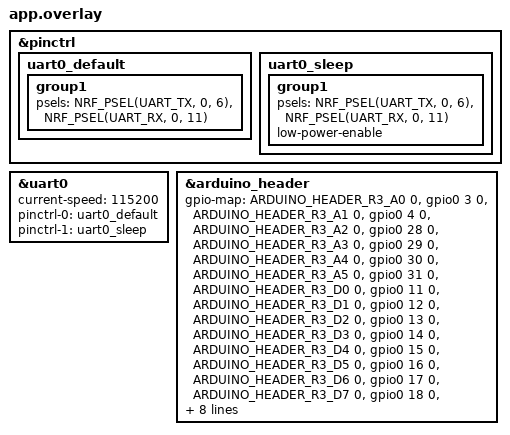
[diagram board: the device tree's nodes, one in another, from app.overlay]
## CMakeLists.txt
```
cmake_minimum_required(VERSION 3.20.0)
find_package(Zephyr REQUIRED HINTS $ENV{ZEPHYR_BASE})
project(gps_trying)

# debugging setup, sets whether we have straight UART outptu or parsed GPS data output
if(CONFIG_GPS_PARSED_OUTPUT)
    target_sources(app PRIVATE src/main_parsed.c)
else()
    target_sources(app PRIVATE src/main_nmea.c)
endif()
```

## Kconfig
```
config GPS_PARSED_OUTPUT
    bool "Use parsed GPS output instead of raw NMEA strings"
    default n

source "Kconfig.zephyr"
```

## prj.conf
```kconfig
# Enables the serial/UART driver subsystem in Zephyr - UART doesn't work without
CONFIG_SERIAL=y

# Uses interrupt-driven UART instead of polling - uart_cb firiing mechanism when GPS data arrives, instead of constant poll
# *May show linter warning, but the dependencies mentioned are auto-enabled by the nrf52832 (SERIAL_SUPPORT_INTERRUPT)
CONFIG_UART_INTERRUPT_DRIVEN=y

# RTT output instead of COM port - can be removed if we switch
# to a different debug method like a second UART 
# but on nRF52832 with only one UART available this works 
CONFIG_USE_SEGGER_RTT=y

# Routes printk() output to the RTT terminal
CONFIG_RTT_CONSOLE=y

# Disables routing printk() to uart0
# Turning this off frees uart0 exclusively for GPS data
CONFIG_UART_CONSOLE=n

# Switch between raw NMEA output and parsed GPS output.
# Set to y for parsed output, n for raw NMEA strings.
CONFIG_GPS_PARSED_OUTPUT=n

# Only needed when CONFIG_GPS_PARSED_OUTPUT=y
# CONFIG_FPU=y
# CONFIG_CBPRINTF_FP_SUPPORT=y
```

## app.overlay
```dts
/* Pin control configuration for uart0 */

&pinctrl {
    uart0_default: uart0_default {
        group1 {
        
            // Active pin state - TX on P0.06, RX on P0.11
            psels = <NRF_PSEL(UART_TX, 0, 6)>,
                    <NRF_PSEL(UART_RX, 0, 11)>;
        };
    };
    uart0_sleep: uart0_sleep {
        group1 {

            // Sleep pin state - same pins but low power mode enabled
            psels = <NRF_PSEL(UART_TX, 0, 6)>,
                    <NRF_PSEL(UART_RX, 0, 11)>;
            low-power-enable;
        };
    };
};

/* UART0 peripheral configuration - used for GPS NMEA data at 9600 baud */
&uart0 {
    status = "okay";
    current-speed = <115200>;
    // state 0: active
    pinctrl-0 = <&uart0_default>;
    // state 1: sleep
    pinctrl-1 = <&uart0_sleep>;
    pinctrl-names = "default", "sleep";
};
&arduino_header {
    gpio-map = <ARDUINO_HEADER_R3_A0 0 &gpio0 3 0>,
               <ARDUINO_HEADER_R3_A1 0 &gpio0 4 0>,
               <ARDUINO_HEADER_R3_A2 0 &gpio0 28 0>,
               <ARDUINO_HEADER_R3_A3 0 &gpio0 29 0>,
               <ARDUINO_HEADER_R3_A4 0 &gpio0 30 0>,
               <ARDUINO_HEADER_R3_A5 0 &gpio0 31 0>,
               <ARDUINO_HEADER_R3_D0 0 &gpio0 11 0>,
               <ARDUINO_HEADER_R3_D1 0 &gpio0 12 0>,
               <ARDUINO_HEADER_R3_D2 0 &gpio0 13 0>,
               <ARDUINO_HEADER_R3_D3 0 &gpio0 14 0>,
               <ARDUINO_HEADER_R3_D4 0 &gpio0 15 0>,
               <ARDUINO_HEADER_R3_D5 0 &gpio0 16 0>,
               <ARDUINO_HEADER_R3_D6 0 &gpio0 17 0>,
               <ARDUINO_HEADER_R3_D7 0 &gpio0 18 0>,
               <ARDUINO_HEADER_R3_D8 0 &gpio0 19 0>,
               <ARDUINO_HEADER_R3_D9 0 &gpio0 20 0>,
               <ARDUINO_HEADER_R3_D10 0 &gpio0 22 0>,
               <ARDUINO_HEADER_R3_D11 0 &gpio0 23 0>,
               <ARDUINO_HEADER_R3_D12 0 &gpio0 24 0>,
               <ARDUINO_HEADER_R3_D13 0 &gpio0 25 0>,
               <ARDUINO_HEADER_R3_D14 0 &gpio0 26 0>,
               <ARDUINO_HEADER_R3_D15 0 &gpio0 27 0>;
};
```

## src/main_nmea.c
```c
#include <zephyr/kernel.h>
#include <zephyr/device.h>
#include <zephyr/drivers/uart.h>

#define GPS_UART     DEVICE_DT_GET(DT_NODELABEL(uart0))
#define NMEA_MAX_LEN 100

static const struct device *gps_uart = GPS_UART;
static char line_buf[NMEA_MAX_LEN];
static int  line_pos = 0;

static void uart_cb(const struct device *dev, void *user_data)
{
    printk("UART callback triggered\n");
    uint8_t c;
    if (!uart_irq_update(dev) || !uart_irq_rx_ready(dev)) return;

    while (uart_fifo_read(dev, &c, 1) == 1) {
        printk("%d\n", c);
        // if (c == '\n' && line_pos > 0) {
        //     line_buf[line_pos] = '\0';
        //     printk("%s\n", line_buf);
        //     line_pos = 0;
        // } else if (c != '\r' && line_pos < NMEA_MAX_LEN - 1) {
        //     line_buf[line_pos++] = c;
        // }
    }
}

int main(void)
{
    if (!device_is_ready(gps_uart)) {
        printk("GPS UART not ready\n");
        return -1;
    }

    uart_irq_callback_set(gps_uart, uart_cb);
    uart_irq_rx_enable(gps_uart);
    printk("GPS reader started, waiting for NMEA...\n");

    while (1) {
        k_sleep(K_FOREVER);
    }

    return 0;
}
```

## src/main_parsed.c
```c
#include <zephyr/kernel.h>
#include <zephyr/device.h>
#include <zephyr/drivers/uart.h>
#include <string.h>
#include <stdlib.h>

#define GPS_UART      DEVICE_DT_GET(DT_NODELABEL(uart0))
#define NMEA_MAX_LEN  100

static const struct device *gps_uart = GPS_UART;
static char line_buf[NMEA_MAX_LEN];
static int  line_pos = 0;

static volatile bool new_fix = false;

static char g_time[16];
static char g_lat[16];
static char g_lat_dir[4];
static char g_lon[16];
static char g_lon_dir[4];
static int  g_satellites;
static char g_altitude[16];
static int  g_fix_quality;

static bool get_field(const char *sentence, int index, char *out, size_t out_len)
{
    int field = 0;
    const char *p = sentence;

    while (*p && field < index) {
        if (*p == ',') field++;
        p++;
    }

    if (!*p) { out[0] = '\0'; return false; }

    size_t i = 0;
    while (*p && *p != ',' && *p != '*' && i < out_len - 1) {
        out[i++] = *p++;
    }
    out[i] = '\0';
    return i > 0;
}

static float nmea_to_decimal(const char *raw, const char *dir)
{
    if (raw[0] == '\0') return 0.0f;
    float raw_val = atof(raw);
    int   degrees = (int)(raw_val / 100);
    float minutes = raw_val - (degrees * 100);
    float decimal = degrees + (minutes / 60.0f);
    if (dir[0] == 'S' || dir[0] == 'W') decimal = -decimal;
    return decimal;
}

static void parse_gga(const char *sentence)
{
    char field[32];
    get_field(sentence, 1, g_time,     sizeof(g_time));
    get_field(sentence, 2, g_lat,      sizeof(g_lat));
    get_field(sentence, 3, g_lat_dir,  sizeof(g_lat_dir));
    get_field(sentence, 4, g_lon,      sizeof(g_lon));
    get_field(sentence, 5, g_lon_dir,  sizeof(g_lon_dir));
    get_field(sentence, 6, field,      sizeof(field)); g_fix_quality = atoi(field);
    get_field(sentence, 7, field,      sizeof(field)); g_satellites  = atoi(field);
    get_field(sentence, 9, g_altitude, sizeof(g_altitude));
    new_fix = true;
}

static void uart_cb(const struct device *dev, void *user_data)
{
    uint8_t c;
    if (!uart_irq_update(dev) || !uart_irq_rx_ready(dev)) return;

    while (uart_fifo_read(dev, &c, 1) == 1) {
        if (c == '\n' && line_pos > 0) {
            line_buf[line_pos] = '\0';
            if (strncmp(line_buf, "$GNGGA", 6) == 0 ||
                strncmp(line_buf, "$GPGGA", 6) == 0) {
                parse_gga(line_buf);
            }
            line_pos = 0;
        } else if (c != '\r' && line_pos < NMEA_MAX_LEN - 1) {
            line_buf[line_pos++] = c;
        }
    }
}

int main(void)
{

    if (!device_is_ready(gps_uart)) {
        printk("GPS UART not ready\n");
        return -1;
    }

    uart_irq_callback_set(gps_uart, uart_cb);
    uart_irq_rx_enable(gps_uart);
    printk("GPS reader started...\n");

    while (1) {
        k_sleep(K_SECONDS(5));

        if (!new_fix) {
            printk("--- No GPS fix yet ---\n");
            continue;
        }

        new_fix = false;

        float lat = nmea_to_decimal(g_lat, g_lat_dir);
        float lon = nmea_to_decimal(g_lon, g_lon_dir);



        char hh[3] = { g_time[0], g_time[1], '\0' };
        char mm[3] = { g_time[2], g_time[3], '\0' };
        char ss[3] = { g_time[4], g_time[5], '\0' };

        printk("=============================\n");
        printk("  Time (UTC):  %s:%s:%s\n", hh, mm, ss);
        printk("  Latitude:    %.6f\n", (double)lat);
        printk("  Longitude:   %.6f\n", (double)lon);
        printk("  Altitude:    %s m\n", g_altitude);
        printk("  Satellites:  %d\n",   g_satellites);
        printk("  Fix quality: %s\n",   g_fix_quality == 1 ? "GPS" :
                                        g_fix_quality == 2 ? "DGPS" : "None");
        printk("=============================\n");
    }

    return 0;
}
```
